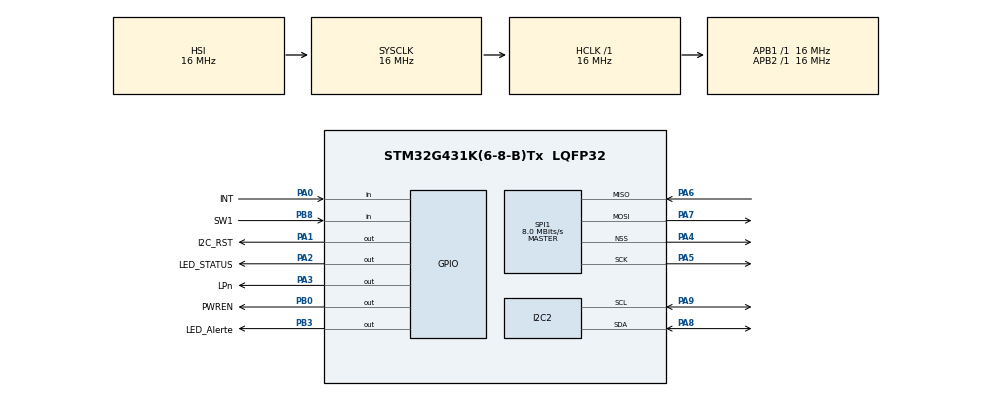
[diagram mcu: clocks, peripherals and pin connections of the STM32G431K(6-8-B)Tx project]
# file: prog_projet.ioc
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I2C2.Timing=0x00503D58
Mcu.Family=STM32G4
Mcu.Name=STM32G431K(6-8-B)Tx
Mcu.Package=LQFP32
NVIC.PriorityGroup=NVIC_PRIORITYGROUP_4
PA0.GPIO_Label=INT
PA0.Signal=GPIO_Input
PA1.GPIO_Label=I2C_RST
PA1.Signal=GPIO_Output
PA13.Mode=Serial_Wire
PA13.Signal=SYS_JTMS-SWDIO
PA14.Mode=Serial_Wire
PA14.Signal=SYS_JTCK-SWCLK
PA2.GPIO_Label=LED_STATUS
PA2.Signal=GPIO_Output
PA3.GPIO_Label=LPn
PA3.Signal=GPIO_Output
PA4.Mode=NSS_Signal_Hard_Output
PA4.Signal=SPI1_NSS
PA5.Mode=Full_Duplex_Master
PA5.Signal=SPI1_SCK
PA6.Mode=Full_Duplex_Master
PA6.Signal=SPI1_MISO
PA7.Mode=Full_Duplex_Master
PA7.Signal=SPI1_MOSI
PA8.Mode=I2C
PA8.Signal=I2C2_SDA
PA9.Mode=I2C
PA9.Signal=I2C2_SCL
PB0.GPIO_Label=PWREN
PB0.Signal=GPIO_Output
PB3.GPIO_Label=LED_Alerte
PB3.Signal=GPIO_Output
PB8-BOOT0.GPIO_Label=SW1
PB8-BOOT0.Signal=GPIO_Input
ProjectManager.HeapSize=0x200
ProjectManager.StackSize=0x400
ProjectManager.TargetToolchain=STM32CubeIDE
RCC.AHBFreq_Value=16000000
RCC.APB1Freq_Value=16000000
RCC.APB1TimFreq_Value=16000000
RCC.APB2Freq_Value=16000000
RCC.APB2TimFreq_Value=16000000
RCC.CortexFreq_Value=16000000
RCC.EXTERNAL_CLOCK_VALUE=12288000
RCC.HCLKFreq_Value=16000000
RCC.HSE_VALUE=8000000
RCC.HSI48_VALUE=48000000
RCC.HSI_VALUE=16000000
RCC.LSE_VALUE=32768
RCC.SYSCLKFreq_VALUE=16000000
RCC.USBFreq_Value=64000000
RCC.VCOOutputFreq_Value=128000000
SPI1.CalculateBaudRate=8.0 MBits/s
SPI1.Direction=SPI_DIRECTION_2LINES
SPI1.Mode=SPI_MODE_MASTER
SPI1.VirtualNSS=VM_NSSHARD
SPI1.VirtualType=VM_MASTER
VP_SYS_VS_DBSignals.Mode=DisableDeadBatterySignals
board=custom

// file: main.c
/* USER CODE BEGIN Header */
/**
  ******************************************************************************
  * @file           : main.c
  * @brief          : Main program body
  ******************************************************************************
  * @attention
  *
  * Copyright (c) 2026 STMicroelectronics.
  * All rights reserved.
  *
  * This software is licensed under terms that can be found in the LICENSE file
  * in the root directory of this software component.
  * If no LICENSE file comes with this software, it is provided AS-IS.
  *
  ******************************************************************************
  */
/* USER CODE END Header */
#include "main.h"

/* USER CODE BEGIN Includes */

#include "vl53l5cx_api.h" // Ou le nom de ton fichier .h de driver

/* USER CODE END Includes */

I2C_HandleTypeDef hi2c2;

SPI_HandleTypeDef hspi1;

void SystemClock_Config(void);
static void MX_GPIO_Init(void);
static void MX_I2C2_Init(void);
static void MX_SPI1_Init(void);

int main(void)
{

  /* MCU Configuration--------------------------------------------------------*/

  /* Reset of all peripherals, Initializes the Flash interface and the Systick. */
  HAL_Init();

  /* Configure the system clock */
  SystemClock_Config();

  /* Initialize all configured peripherals */
  MX_GPIO_Init();
  MX_I2C2_Init();
  MX_SPI1_Init();
  /* USER CODE BEGIN 2 */
  setup();
  /* USER CODE END 2 */

  /* Infinite loop */
  while (1)
  {

  }
}

void SystemClock_Config(void)
{
  RCC_OscInitTypeDef RCC_OscInitStruct = {0};
  RCC_ClkInitTypeDef RCC_ClkInitStruct = {0};

  /** Configure the main internal regulator output voltage
  */
  HAL_PWREx_ControlVoltageScaling(PWR_REGULATOR_VOLTAGE_SCALE1);

  /** Initializes the RCC Oscillators according to the specified parameters
  * in the RCC_OscInitTypeDef structure.
  */
  RCC_OscInitStruct.OscillatorType = RCC_OSCILLATORTYPE_HSI;
  RCC_OscInitStruct.HSIState = RCC_HSI_ON;
  RCC_OscInitStruct.HSICalibrationValue = RCC_HSICALIBRATION_DEFAULT;
  RCC_OscInitStruct.PLL.PLLState = RCC_PLL_NONE;
  if (HAL_RCC_OscConfig(&RCC_OscInitStruct) != HAL_OK)
  {
    Error_Handler();
  }

  /** Initializes the CPU, AHB and APB buses clocks
  */
  RCC_ClkInitStruct.ClockType = RCC_CLOCKTYPE_HCLK|RCC_CLOCKTYPE_SYSCLK
                              |RCC_CLOCKTYPE_PCLK1|RCC_CLOCKTYPE_PCLK2;
  RCC_ClkInitStruct.SYSCLKSource = RCC_SYSCLKSOURCE_HSI;
  RCC_ClkInitStruct.AHBCLKDivider = RCC_SYSCLK_DIV1;
  RCC_ClkInitStruct.APB1CLKDivider = RCC_HCLK_DIV1;
  RCC_ClkInitStruct.APB2CLKDivider = RCC_HCLK_DIV1;

  if (HAL_RCC_ClockConfig(&RCC_ClkInitStruct, FLASH_LATENCY_0) != HAL_OK)
  {
    Error_Handler();
  }
}

static void MX_I2C2_Init(void)
{

  hi2c2.Instance = I2C2;
  hi2c2.Init.Timing = 0x00503D58;
  hi2c2.Init.OwnAddress1 = 0;
  hi2c2.Init.AddressingMode = I2C_ADDRESSINGMODE_7BIT;
  hi2c2.Init.DualAddressMode = I2C_DUALADDRESS_DISABLE;
  hi2c2.Init.OwnAddress2 = 0;
  hi2c2.Init.OwnAddress2Masks = I2C_OA2_NOMASK;
  hi2c2.Init.GeneralCallMode = I2C_GENERALCALL_DISABLE;
  hi2c2.Init.NoStretchMode = I2C_NOSTRETCH_DISABLE;
  if (HAL_I2C_Init(&hi2c2) != HAL_OK)
  {
    Error_Handler();
  }

  /** Configure Analogue filter
  */
  if (HAL_I2CEx_ConfigAnalogFilter(&hi2c2, I2C_ANALOGFILTER_ENABLE) != HAL_OK)
  {
    Error_Handler();
  }

  /** Configure Digital filter
  */
  if (HAL_I2CEx_ConfigDigitalFilter(&hi2c2, 0) != HAL_OK)
  {
    Error_Handler();
  }

}

static void MX_SPI1_Init(void)
{

  /* SPI1 parameter configuration*/
  hspi1.Instance = SPI1;
  hspi1.Init.Mode = SPI_MODE_MASTER;
  hspi1.Init.Direction = SPI_DIRECTION_2LINES;
  hspi1.Init.DataSize = SPI_DATASIZE_4BIT;
  hspi1.Init.CLKPolarity = SPI_POLARITY_LOW;
  hspi1.Init.CLKPhase = SPI_PHASE_1EDGE;
  hspi1.Init.NSS = SPI_NSS_HARD_OUTPUT;
  hspi1.Init.BaudRatePrescaler = SPI_BAUDRATEPRESCALER_2;
  hspi1.Init.FirstBit = SPI_FIRSTBIT_MSB;
  hspi1.Init.TIMode = SPI_TIMODE_DISABLE;
  hspi1.Init.CRCCalculation = SPI_CRCCALCULATION_DISABLE;
  hspi1.Init.CRCPolynomial = 7;
  hspi1.Init.CRCLength = SPI_CRC_LENGTH_DATASIZE;
  hspi1.Init.NSSPMode = SPI_NSS_PULSE_ENABLE;
  if (HAL_SPI_Init(&hspi1) != HAL_OK)
  {
    Error_Handler();
  }

}

static void MX_GPIO_Init(void)
{
  GPIO_InitTypeDef GPIO_InitStruct = {0};

  /* GPIO Ports Clock Enable */
  __HAL_RCC_GPIOA_CLK_ENABLE();
  __HAL_RCC_GPIOB_CLK_ENABLE();

  /*Configure GPIO pin Output Level */
  HAL_GPIO_WritePin(GPIOA, I2C_RST_Pin|LED_STATUS_Pin|LPn_Pin, GPIO_PIN_RESET);

  /*Configure GPIO pin Output Level */
  HAL_GPIO_WritePin(GPIOB, PWREN_Pin|LED_Alerte_Pin, GPIO_PIN_RESET);

  /*Configure GPIO pin : INT_Pin */
  GPIO_InitStruct.Pin = INT_Pin;
  GPIO_InitStruct.Mode = GPIO_MODE_INPUT;
  GPIO_InitStruct.Pull = GPIO_NOPULL;
  HAL_GPIO_Init(INT_GPIO_Port, &GPIO_InitStruct);

  /*Configure GPIO pins : I2C_RST_Pin LED_STATUS_Pin LPn_Pin */
  GPIO_InitStruct.Pin = I2C_RST_Pin|LED_STATUS_Pin|LPn_Pin;
  GPIO_InitStruct.Mode = GPIO_MODE_OUTPUT_PP;
  GPIO_InitStruct.Pull = GPIO_NOPULL;
  GPIO_InitStruct.Speed = GPIO_SPEED_FREQ_LOW;
  HAL_GPIO_Init(GPIOA, &GPIO_InitStruct);

  /*Configure GPIO pins : PWREN_Pin LED_Alerte_Pin */
  GPIO_InitStruct.Pin = PWREN_Pin|LED_Alerte_Pin;
  GPIO_InitStruct.Mode = GPIO_MODE_OUTPUT_PP;
  GPIO_InitStruct.Pull = GPIO_NOPULL;
  GPIO_InitStruct.Speed = GPIO_SPEED_FREQ_LOW;
  HAL_GPIO_Init(GPIOB, &GPIO_InitStruct);

  /*Configure GPIO pin : SW1_Pin */
  GPIO_InitStruct.Pin = SW1_Pin;
  GPIO_InitStruct.Mode = GPIO_MODE_INPUT;
  GPIO_InitStruct.Pull = GPIO_NOPULL;
  HAL_GPIO_Init(SW1_GPIO_Port, &GPIO_InitStruct);

}

void Error_Handler(void)
{
  __disable_irq();
  while (1)
  {
  }
}
